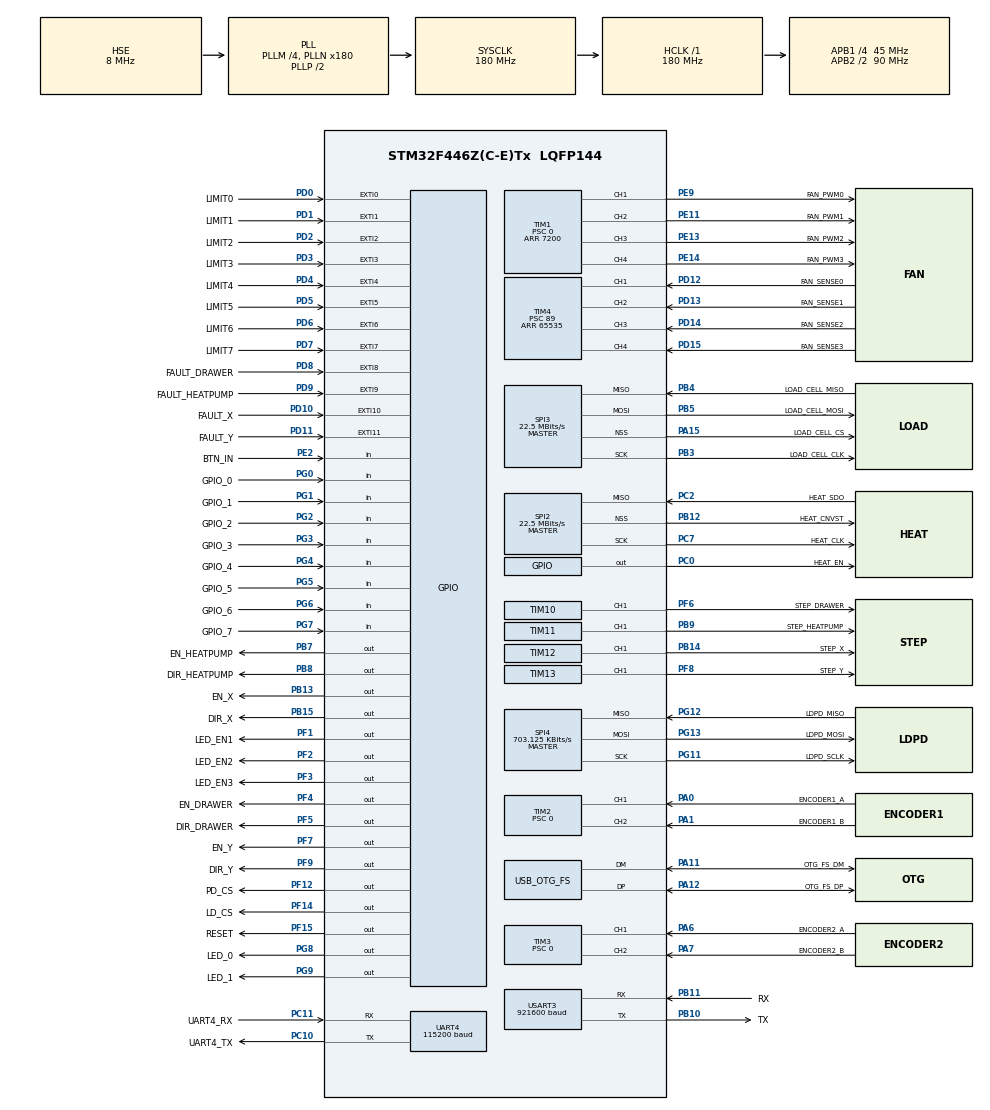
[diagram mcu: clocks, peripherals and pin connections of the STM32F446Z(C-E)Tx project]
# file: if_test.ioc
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Dma.Request0=USART3_RX
Dma.Request1=USART3_TX
Dma.USART3_RX.0.Direction=DMA_PERIPH_TO_MEMORY
Dma.USART3_RX.0.FIFOMode=DMA_FIFOMODE_DISABLE
Dma.USART3_RX.0.Instance=DMA1_Stream1
Dma.USART3_RX.0.MemDataAlignment=DMA_MDATAALIGN_BYTE
Dma.USART3_RX.0.MemInc=DMA_MINC_ENABLE
Dma.USART3_RX.0.Mode=DMA_NORMAL
Dma.USART3_RX.0.PeriphDataAlignment=DMA_PDATAALIGN_BYTE
Dma.USART3_RX.0.PeriphInc=DMA_PINC_DISABLE
Dma.USART3_RX.0.Priority=DMA_PRIORITY_LOW
Dma.USART3_TX.1.Direction=DMA_MEMORY_TO_PERIPH
Dma.USART3_TX.1.FIFOMode=DMA_FIFOMODE_DISABLE
Dma.USART3_TX.1.Instance=DMA1_Stream3
Dma.USART3_TX.1.MemDataAlignment=DMA_MDATAALIGN_BYTE
Dma.USART3_TX.1.MemInc=DMA_MINC_ENABLE
Dma.USART3_TX.1.Mode=DMA_NORMAL
Dma.USART3_TX.1.PeriphDataAlignment=DMA_PDATAALIGN_BYTE
Dma.USART3_TX.1.PeriphInc=DMA_PINC_DISABLE
Dma.USART3_TX.1.Priority=DMA_PRIORITY_LOW
FREERTOS.HEAP_NUMBER=4
FREERTOS.INCLUDE_eTaskGetState=1
FREERTOS.INCLUDE_pcTaskGetTaskName=0
FREERTOS.INCLUDE_uxTaskGetStackHighWaterMark=1
FREERTOS.INCLUDE_uxTaskGetStackHighWaterMark2=0
FREERTOS.INCLUDE_uxTaskPriorityGet=1
FREERTOS.INCLUDE_vTaskCleanUpResources=0
FREERTOS.INCLUDE_vTaskDelay=1
FREERTOS.INCLUDE_vTaskDelayUntil=1
FREERTOS.INCLUDE_vTaskDelete=1
FREERTOS.INCLUDE_vTaskPrioritySet=1
FREERTOS.INCLUDE_vTaskSuspend=1
FREERTOS.INCLUDE_xEventGroupSetBitFromISR=0
FREERTOS.INCLUDE_xQueueGetMutexHolder=1
FREERTOS.INCLUDE_xSemaphoreGetMutexHolder=0
FREERTOS.INCLUDE_xTaskAbortDelay=0
FREERTOS.INCLUDE_xTaskGetCurrentTaskHandle=1
FREERTOS.INCLUDE_xTaskGetHandle=0
FREERTOS.INCLUDE_xTaskGetSchedulerState=1
FREERTOS.INCLUDE_xTaskResumeFromISR=1
FREERTOS.INCLUDE_xTimerPendFunctionCall=1
FREERTOS.Tasks01=defaultTask,24,128,StartDefaultTask,Default,NULL,Dynamic,NULL,NULL
FREERTOS.configCHECK_FOR_STACK_OVERFLOW=0
FREERTOS.configENABLE_BACKWARD_COMPATIBILITY=1
FREERTOS.configENABLE_FPU=0
FREERTOS.configGENERATE_RUN_TIME_STATS=0
FREERTOS.configIDLE_SHOULD_YIELD=1
FREERTOS.configLIBRARY_LOWEST_INTERRUPT_PRIORITY=15
FREERTOS.configLIBRARY_MAX_SYSCALL_INTERRUPT_PRIORITY=5
FREERTOS.configMAX_CO_ROUTINE_PRIORITIES=2
FREERTOS.configMAX_TASK_NAME_LEN=16
FREERTOS.configMINIMAL_STACK_SIZE=128
FREERTOS.configQUEUE_REGISTRY_SIZE=8
FREERTOS.configRECORD_STACK_HIGH_ADDRESS=0
FREERTOS.configTICK_RATE_HZ=1000
FREERTOS.configTIMER_QUEUE_LENGTH=10
FREERTOS.configTIMER_TASK_PRIORITY=2
FREERTOS.configTIMER_TASK_STACK_DEPTH=256
FREERTOS.configTOTAL_HEAP_SIZE=40000
FREERTOS.configUSE_APPLICATION_TASK_TAG=0
FREERTOS.configUSE_COUNTING_SEMAPHORES=1
FREERTOS.configUSE_CO_ROUTINES=0
FREERTOS.configUSE_DAEMON_TASK_STARTUP_HOOK=0
FREERTOS.configUSE_IDLE_HOOK=0
FREERTOS.configUSE_MALLOC_FAILED_HOOK=0
FREERTOS.configUSE_MUTEXES=1
FREERTOS.configUSE_NEWLIB_REENTRANT=1
FREERTOS.configUSE_OS2_EVENTFLAGS_FROM_ISR=1
FREERTOS.configUSE_OS2_MUTEX=1
FREERTOS.configUSE_OS2_THREAD_ENUMERATE=1
FREERTOS.configUSE_OS2_THREAD_FLAGS=1
FREERTOS.configUSE_OS2_THREAD_SUSPEND_RESUME=1
FREERTOS.configUSE_OS2_TIMER=1
FREERTOS.configUSE_POSIX_ERRNO=0
FREERTOS.configUSE_PREEMPTION=1
FREERTOS.configUSE_RECURSIVE_MUTEXES=1
FREERTOS.configUSE_STATS_FORMATTING_FUNCTIONS=0
FREERTOS.configUSE_TASK_NOTIFICATIONS=1
FREERTOS.configUSE_TICKLESS_IDLE=0
FREERTOS.configUSE_TICK_HOOK=0
FREERTOS.configUSE_TRACE_FACILITY=1
FREERTOS.copyHeapFile=1
Mcu.Family=STM32F4
Mcu.Name=STM32F446Z(C-E)Tx
Mcu.Package=LQFP144
NVIC.DMA1_Stream1_IRQn=true\:5\:0\:false\:false\:true\:true\:false\:true\:true
NVIC.DMA1_Stream3_IRQn=true\:5\:0\:false\:false\:true\:true\:false\:true\:true
NVIC.EXTI0_IRQn=true\:5\:0\:false\:false\:true\:true\:true\:true\:true
NVIC.EXTI15_10_IRQn=true\:5\:0\:false\:false\:true\:true\:true\:true\:true
NVIC.EXTI1_IRQn=true\:5\:0\:false\:false\:true\:true\:true\:true\:true
NVIC.EXTI2_IRQn=true\:5\:0\:false\:false\:true\:true\:true\:true\:true
NVIC.EXTI3_IRQn=true\:5\:0\:false\:false\:true\:true\:true\:true\:true
NVIC.EXTI4_IRQn=true\:5\:0\:false\:false\:true\:true\:true\:true\:true
NVIC.EXTI9_5_IRQn=true\:5\:0\:false\:false\:true\:true\:true\:true\:true
NVIC.PriorityGroup=NVIC_PRIORITYGROUP_4
NVIC.SPI4_IRQn=true\:5\:0\:false\:false\:true\:true\:true\:true\:true
NVIC.TIM1_BRK_TIM9_IRQn=true\:5\:0\:false\:false\:true\:true\:true\:true\:true
NVIC.TIM1_TRG_COM_TIM11_IRQn=true\:5\:0\:false\:false\:true\:true\:true\:true\:true
NVIC.TIM1_UP_TIM10_IRQn=true\:5\:0\:false\:false\:true\:true\:true\:true\:true
NVIC.TIM4_IRQn=true\:5\:0\:false\:false\:true\:true\:true\:true\:true
NVIC.TIM8_BRK_TIM12_IRQn=true\:5\:0\:false\:false\:true\:true\:true\:true\:true
NVIC.TIM8_TRG_COM_TIM14_IRQn=true\:15\:0\:false\:false\:true\:false\:true\:true\:true
NVIC.TIM8_UP_TIM13_IRQn=true\:5\:0\:false\:false\:true\:true\:true\:true\:true
NVIC.TimeBase=TIM8_TRG_COM_TIM14_IRQn
NVIC.TimeBaseIP=TIM14
NVIC.USART3_IRQn=true\:5\:0\:false\:false\:true\:true\:true\:true\:true
PA0-WKUP.GPIO_Label=ENCODER1_A
PA0-WKUP.Signal=S_TIM2_CH1_ETR
PA1.GPIO_Label=ENCODER1_B
PA1.Signal=S_TIM2_CH2
PA11.GPIO_Label=OTG_FS_DM
PA11.Mode=Device_Only
PA11.Signal=USB_OTG_FS_DM
PA12.GPIO_Label=OTG_FS_DP
PA12.Mode=Device_Only
PA12.Signal=USB_OTG_FS_DP
PA13.Mode=Serial_Wire
PA13.Signal=SYS_JTMS-SWDIO
PA14.Mode=Serial_Wire
PA14.Signal=SYS_JTCK-SWCLK
PA15.GPIO_Label=LOAD_CELL_CS
PA15.Mode=NSS_Signal_Hard_Output
PA15.Signal=SPI3_NSS
PA6.GPIO_Label=ENCODER2_A
PA6.Signal=S_TIM3_CH1
PA7.GPIO_Label=ENCODER2_B
PA7.Signal=S_TIM3_CH2
PB10.GPIO_Label=TX
PB10.Mode=Asynchronous
PB10.Signal=USART3_TX
PB11.GPIO_Label=RX
PB11.Mode=Asynchronous
PB11.Signal=USART3_RX
PB12.GPIO_Label=HEAT_CNVST
PB12.Mode=NSS_Signal_Hard_Output
PB12.Signal=SPI2_NSS
PB13.GPIO_Label=EN_X
PB13.Signal=GPIO_Output
PB14.GPIO_Label=STEP_X
PB14.Signal=S_TIM12_CH1
PB15.GPIO_Label=DIR_X
PB15.Signal=GPIO_Output
PB3.GPIO_Label=LOAD_CELL_CLK
PB3.Mode=Full_Duplex_Master
PB3.Signal=SPI3_SCK
PB4.GPIO_Label=LOAD_CELL_MISO
PB4.Mode=Full_Duplex_Master
PB4.Signal=SPI3_MISO
PB5.GPIO_Label=LOAD_CELL_MOSI
PB5.Mode=Full_Duplex_Master
PB5.Signal=SPI3_MOSI
PB7.GPIO_Label=EN_HEATPUMP
PB7.Signal=GPIO_Output
PB8.GPIO_Label=DIR_HEATPUMP
PB8.Signal=GPIO_Output
PB9.GPIO_Label=STEP_HEATPUMP
PB9.Signal=S_TIM11_CH1
PC0.GPIO_Label=HEAT_EN
PC0.Signal=GPIO_Output
PC10.GPIO_Label=UART4_TX
PC10.Mode=Asynchronous
PC10.Signal=UART4_TX
PC11.GPIO_Label=UART4_RX
PC11.Mode=Asynchronous
PC11.Signal=UART4_RX
PC2.GPIO_Label=HEAT_SDO
PC2.Mode=RX_Only_Simplex_Unidirect_Master
PC2.Signal=SPI2_MISO
PC7.GPIO_Label=HEAT_CLK
PC7.Mode=RX_Only_Simplex_Unidirect_Master
PC7.Signal=SPI2_SCK
PD0.GPIO_Label=LIMIT0
PD0.GPIO_ModeDefaultEXTI=GPIO_MODE_IT_FALLING
PD0.Signal=GPXTI0
PD1.GPIO_Label=LIMIT1
PD1.GPIO_ModeDefaultEXTI=GPIO_MODE_IT_FALLING
PD1.Signal=GPXTI1
PD10.GPIO_Label=FAULT_X
PD10.GPIO_ModeDefaultEXTI=GPIO_MODE_IT_FALLING
PD10.Signal=GPXTI10
PD11.GPIO_Label=FAULT_Y
PD11.Signal=GPXTI11
PD12.GPIO_Label=FAN_SENSE0
PD12.Signal=S_TIM4_CH1
PD13.GPIO_Label=FAN_SENSE1
PD13.Signal=S_TIM4_CH2
PD14.GPIO_Label=FAN_SENSE2
PD14.Signal=S_TIM4_CH3
PD15.GPIO_Label=FAN_SENSE3
PD15.Signal=S_TIM4_CH4
PD2.GPIO_Label=LIMIT2
PD2.GPIO_ModeDefaultEXTI=GPIO_MODE_IT_FALLING
PD2.Signal=GPXTI2
PD3.GPIO_Label=LIMIT3
PD3.GPIO_ModeDefaultEXTI=GPIO_MODE_IT_FALLING
PD3.Signal=GPXTI3
PD4.GPIO_Label=LIMIT4
PD4.GPIO_ModeDefaultEXTI=GPIO_MODE_IT_FALLING
PD4.Signal=GPXTI4
PD5.GPIO_Label=LIMIT5
PD5.GPIO_ModeDefaultEXTI=GPIO_MODE_IT_FALLING
PD5.Signal=GPXTI5
PD6.GPIO_Label=LIMIT6
PD6.GPIO_ModeDefaultEXTI=GPIO_MODE_IT_FALLING
PD6.Signal=GPXTI6
PD7.GPIO_Label=LIMIT7
PD7.GPIO_ModeDefaultEXTI=GPIO_MODE_IT_FALLING
PD7.Signal=GPXTI7
PD8.GPIO_Label=FAULT_DRAWER
PD8.GPIO_ModeDefaultEXTI=GPIO_MODE_IT_FALLING
PD8.Signal=GPXTI8
PD9.GPIO_Label=FAULT_HEATPUMP
PD9.GPIO_ModeDefaultEXTI=GPIO_MODE_IT_FALLING
PD9.Signal=GPXTI9
PE11.GPIO_Label=FAN_PWM1
PE11.Signal=S_TIM1_CH2
PE13.GPIO_Label=FAN_PWM2
PE13.Signal=S_TIM1_CH3
PE14.GPIO_Label=FAN_PWM3
PE14.Signal=S_TIM1_CH4
PE2.GPIO_Label=BTN_IN
PE2.Signal=GPIO_Input
PE9.GPIO_Label=FAN_PWM0
PE9.Signal=S_TIM1_CH1
PF1.GPIO_Label=LED_EN1
PF1.Signal=GPIO_Output
PF12.GPIO_Label=PD_CS
PF12.Signal=GPIO_Output
PF14.GPIO_Label=LD_CS
PF14.Signal=GPIO_Output
PF15.GPIO_Label=RESET
PF15.Signal=GPIO_Output
PF2.GPIO_Label=LED_EN2
PF2.Signal=GPIO_Output
PF3.GPIO_Label=LED_EN3
PF3.Signal=GPIO_Output
PF4.GPIO_Label=EN_DRAWER
PF4.Signal=GPIO_Output
PF5.GPIO_Label=DIR_DRAWER
PF5.Signal=GPIO_Output
PF6.GPIO_Label=STEP_DRAWER
PF6.Signal=S_TIM10_CH1
PF7.GPIO_Label=EN_Y
PF7.Signal=GPIO_Output
PF8.GPIO_Label=STEP_Y
PF8.Signal=S_TIM13_CH1
PF9.GPIO_Label=DIR_Y
PF9.Signal=GPIO_Output
PG0.GPIO_Label=GPIO_0
PG0.Signal=GPIO_Input
PG1.GPIO_Label=GPIO_1
PG1.Signal=GPIO_Input
PG11.GPIO_Label=LDPD_SCLK
PG11.Mode=Full_Duplex_Master
PG11.Signal=SPI4_SCK
PG12.GPIO_Label=LDPD_MISO
PG12.Mode=Full_Duplex_Master
PG12.Signal=SPI4_MISO
PG13.GPIO_Label=LDPD_MOSI
PG13.Mode=Full_Duplex_Master
PG13.Signal=SPI4_MOSI
PG2.GPIO_Label=GPIO_2
PG2.Signal=GPIO_Input
PG3.GPIO_Label=GPIO_3
PG3.Signal=GPIO_Input
PG4.GPIO_Label=GPIO_4
PG4.Signal=GPIO_Input
PG5.GPIO_Label=GPIO_5
PG5.Signal=GPIO_Input
PG6.GPIO_Label=GPIO_6
PG6.Signal=GPIO_Input
PG7.GPIO_Label=GPIO_7
PG7.Signal=GPIO_Input
PG8.GPIO_Label=LED_0
PG8.Signal=GPIO_Output
PG9.GPIO_Label=LED_1
PG9.Signal=GPIO_Output
PH0-OSC_IN.Mode=HSE-External-Oscillator
PH0-OSC_IN.Signal=RCC_OSC_IN
PH1-OSC_OUT.Mode=HSE-External-Oscillator
PH1-OSC_OUT.Signal=RCC_OSC_OUT
ProjectManager.HeapSize=0x200
ProjectManager.StackSize=0x400
ProjectManager.TargetToolchain=CMake
RCC.AHBFreq_Value=180000000
RCC.APB1CLKDivider=RCC_HCLK_DIV4
RCC.APB1Freq_Value=45000000
RCC.APB1TimFreq_Value=90000000
RCC.APB2CLKDivider=RCC_HCLK_DIV2
RCC.APB2Freq_Value=90000000
RCC.APB2TimFreq_Value=180000000
RCC.CortexFreq_Value=180000000
RCC.HCLKFreq_Value=180000000
RCC.HSE_VALUE=8000000
RCC.PLLM=4
RCC.PLLN=180
RCC.PLLSAIM=8
RCC.PLLSAIP=RCC_PLLSAIP_DIV4
RCC.PWREXT_OverDrive=PWREXT_OverDrive_ACTIVATED
RCC.SYSCLKFreq_VALUE=180000000
RCC.SYSCLKSource=RCC_SYSCLKSOURCE_PLLCLK
RCC.USBCLockSelection=RCC_CLK48CLKSOURCE_PLLSAIP
RCC.USBFreq_Value=48000000
RCC.VCOOutputFreq_Value=360000000
SH.S_TIM10_CH1.0=TIM10_CH1,PWM Generation1 CH1
SH.S_TIM11_CH1.0=TIM11_CH1,PWM Generation1 CH1
SH.S_TIM12_CH1.0=TIM12_CH1,PWM Generation1 CH1
SH.S_TIM13_CH1.0=TIM13_CH1,PWM Generation1 CH1
SH.S_TIM1_CH1.0=TIM1_CH1,PWM Generation1 CH1
SH.S_TIM1_CH2.0=TIM1_CH2,PWM Generation2 CH2
SH.S_TIM1_CH3.0=TIM1_CH3,PWM Generation3 CH3
SH.S_TIM1_CH4.0=TIM1_CH4,PWM Generation4 CH4
SH.S_TIM2_CH1_ETR.0=TIM2_CH1,Encoder_Interface
SH.S_TIM2_CH2.0=TIM2_CH2,Encoder_Interface
SH.S_TIM3_CH1.0=TIM3_CH1,Encoder_Interface
SH.S_TIM3_CH2.0=TIM3_CH2,Encoder_Interface
SH.S_TIM4_CH1.0=TIM4_CH1,Input_Capture1_from_TI1
SH.S_TIM4_CH2.0=TIM4_CH2,Input_Capture2_from_TI2
SH.S_TIM4_CH3.0=TIM4_CH3,Input_Capture3_from_TI3
SH.S_TIM4_CH4.0=TIM4_CH4,Input_Capture4_from_TI4
SPI2.BaudRatePrescaler=SPI_BAUDRATEPRESCALER_2
SPI2.CLKPhase=SPI_PHASE_1EDGE
SPI2.CLKPolarity=SPI_POLARITY_LOW
SPI2.CRCCalculation=SPI_CRCCALCULATION_DISABLE
SPI2.CalculateBaudRate=22.5 MBits/s
SPI2.DataSize=SPI_DATASIZE_8BIT
SPI2.Direction=SPI_DIRECTION_2LINES_RXONLY
SPI2.FirstBit=SPI_FIRSTBIT_MSB
SPI2.Mode=SPI_MODE_MASTER
SPI2.NSS=SPI_NSS_HARD_OUTPUT
SPI2.TIMode=SPI_TIMODE_DISABLE
SPI2.VirtualNSS=VM_NSSHARD
SPI2.VirtualType=VM_MASTER
SPI3.BaudRatePrescaler=SPI_BAUDRATEPRESCALER_2
SPI3.CLKPhase=SPI_PHASE_1EDGE
SPI3.CLKPolarity=SPI_POLARITY_LOW
SPI3.CRCCalculation=SPI_CRCCALCULATION_DISABLE
SPI3.CalculateBaudRate=22.5 MBits/s
SPI3.DataSize=SPI_DATASIZE_8BIT
SPI3.Direction=SPI_DIRECTION_2LINES
SPI3.FirstBit=SPI_FIRSTBIT_MSB
SPI3.Mode=SPI_MODE_MASTER
SPI3.NSS=SPI_NSS_HARD_OUTPUT
SPI3.TIMode=SPI_TIMODE_DISABLE
SPI3.VirtualNSS=VM_NSSHARD
SPI3.VirtualType=VM_MASTER
SPI4.BaudRatePrescaler=SPI_BAUDRATEPRESCALER_128
SPI4.CLKPhase=SPI_PHASE_2EDGE
SPI4.CLKPolarity=SPI_POLARITY_HIGH
SPI4.CRCCalculation=SPI_CRCCALCULATION_DISABLE
SPI4.CalculateBaudRate=703.125 KBits/s
SPI4.DataSize=SPI_DATASIZE_8BIT
SPI4.Direction=SPI_DIRECTION_2LINES
SPI4.FirstBit=SPI_FIRSTBIT_MSB
SPI4.Mode=SPI_MODE_MASTER
SPI4.NSS=SPI_NSS_SOFT
SPI4.TIMode=SPI_TIMODE_DISABLE
SPI4.VirtualType=VM_MASTER
TIM1.AutoReloadPreload=TIM_AUTORELOAD_PRELOAD_DISABLE
TIM1.AutomaticOutput=TIM_AUTOMATICOUTPUT_DISABLE
TIM1.BreakPolarity=TIM_BREAKPOLARITY_HIGH
TIM1.BreakState=TIM_BREAK_DISABLE
TIM1.Channel-PWM\ Generation1\ CH1=TIM_CHANNEL_1
TIM1.Channel-PWM\ Generation2\ CH2=TIM_CHANNEL_2
TIM1.Channel-PWM\ Generation3\ CH3=TIM_CHANNEL_3
TIM1.Channel-PWM\ Generation4\ CH4=TIM_CHANNEL_4
TIM1.ClockDivision=TIM_CLOCKDIVISION_DIV1
TIM1.CounterMode=TIM_COUNTERMODE_UP
TIM1.LockLevel=TIM_LOCKLEVEL_OFF
TIM1.OC1Preload_PWM=ENABLE
TIM1.OC2Preload_PWM=ENABLE
TIM1.OC3Preload_PWM=ENABLE
TIM1.OC4Preload_PWM=ENABLE
TIM1.OCFastMode_PWM-PWM\ Generation1\ CH1=TIM_OCFAST_DISABLE
TIM1.OCFastMode_PWM-PWM\ Generation2\ CH2=TIM_OCFAST_DISABLE
TIM1.OCFastMode_PWM-PWM\ Generation3\ CH3=TIM_OCFAST_DISABLE
TIM1.OCFastMode_PWM-PWM\ Generation4\ CH4=TIM_OCFAST_DISABLE
TIM1.OCIdleState_1=TIM_OCIDLESTATE_RESET
TIM1.OCIdleState_2=TIM_OCIDLESTATE_RESET
TIM1.OCIdleState_3=TIM_OCIDLESTATE_RESET
TIM1.OCIdleState_4=TIM_OCIDLESTATE_RESET
TIM1.OCMode_PWM-PWM\ Generation1\ CH1=TIM_OCMODE_PWM1
TIM1.OCMode_PWM-PWM\ Generation2\ CH2=TIM_OCMODE_PWM1
TIM1.OCMode_PWM-PWM\ Generation3\ CH3=TIM_OCMODE_PWM1
TIM1.OCMode_PWM-PWM\ Generation4\ CH4=TIM_OCMODE_PWM1
TIM1.OCPolarity_1=TIM_OCPOLARITY_HIGH
TIM1.OCPolarity_2=TIM_OCPOLARITY_HIGH
TIM1.OCPolarity_3=TIM_OCPOLARITY_HIGH
TIM1.OCPolarity_4=TIM_OCPOLARITY_HIGH
TIM1.OffStateIDLEMode=TIM_OSSI_DISABLE
TIM1.OffStateRunMode=TIM_OSSR_DISABLE
TIM1.Period=7200
TIM1.Prescaler=0
TIM1.Pulse-PWM\ Generation1\ CH1=0
TIM1.Pulse-PWM\ Generation2\ CH2=0
TIM1.Pulse-PWM\ Generation3\ CH3=0
TIM1.Pulse-PWM\ Generation4\ CH4=0
TIM1.RepetitionCounter=0
TIM1.TIM_MasterOutputTrigger=TIM_TRGO_RESET
TIM1.TIM_MasterSlaveMode=TIM_MASTERSLAVEMODE_DISABLE
TIM10.AutoReloadPreload=TIM_AUTORELOAD_PRELOAD_ENABLE
TIM10.Channel=TIM_CHANNEL_1
TIM10.ClockDivision=TIM_CLOCKDIVISION_DIV1
TIM10.CounterMode=TIM_COUNTERMODE_UP
TIM10.OC1Preload_PWM=ENABLE
TIM10.OCFastMode_PWM=TIM_OCFAST_DISABLE
TIM10.OCMode_PWM=TIM_OCMODE_PWM1
TIM10.OCPolarity_1=TIM_OCPOLARITY_HIGH
TIM10.Period=65535
TIM10.Prescaler=1499
TIM10.Pulse=0
TIM11.AutoReloadPreload=TIM_AUTORELOAD_PRELOAD_ENABLE
TIM11.Channel=TIM_CHANNEL_1
TIM11.ClockDivision=TIM_CLOCKDIVISION_DIV1
TIM11.CounterMode=TIM_COUNTERMODE_UP
TIM11.OC1Preload_PWM=ENABLE
TIM11.OCFastMode_PWM=TIM_OCFAST_DISABLE
TIM11.OCMode_PWM=TIM_OCMODE_PWM1
TIM11.OCPolarity_1=TIM_OCPOLARITY_HIGH
TIM11.Period=65535
TIM11.Prescaler=1499
TIM11.Pulse=0
TIM12.AutoReloadPreload=TIM_AUTORELOAD_PRELOAD_ENABLE
TIM12.Channel-PWM\ Generation1\ CH1=TIM_CHANNEL_1
TIM12.ClockDivision=TIM_CLOCKDIVISION_DIV1
TIM12.CounterMode=TIM_COUNTERMODE_UP
TIM12.OC1Preload_PWM=ENABLE
TIM12.OCFastMode_PWM-PWM\ Generation1\ CH1=TIM_OCFAST_DISABLE
TIM12.OCMode_PWM-PWM\ Generation1\ CH1=TIM_OCMODE_PWM1
TIM12.OCPolarity_1=TIM_OCPOLARITY_HIGH
TIM12.Period=65535
TIM12.Prescaler=749
TIM12.Pulse-PWM\ Generation1\ CH1=0
TIM13.AutoReloadPreload=TIM_AUTORELOAD_PRELOAD_ENABLE
TIM13.Channel=TIM_CHANNEL_1
TIM13.ClockDivision=TIM_CLOCKDIVISION_DIV1
TIM13.CounterMode=TIM_COUNTERMODE_UP
TIM13.OC1Preload_PWM=ENABLE
TIM13.OCFastMode_PWM=TIM_OCFAST_DISABLE
TIM13.OCMode_PWM=TIM_OCMODE_PWM1
TIM13.OCPolarity_1=TIM_OCPOLARITY_HIGH
TIM13.Period=65535
TIM13.Prescaler=749
TIM13.Pulse=0
TIM2.AutoReloadPreload=TIM_AUTORELOAD_PRELOAD_DISABLE
TIM2.ClockDivision=TIM_CLOCKDIVISION_DIV1
TIM2.CounterMode=TIM_COUNTERMODE_UP
TIM2.EncoderMode=TIM_ENCODERMODE_TI12
TIM2.IC1Filter=0
TIM2.IC1Polarity=TIM_ICPOLARITY_RISING
TIM2.IC1Prescaler=TIM_ICPSC_DIV1
TIM2.IC1Selection=TIM_ICSELECTION_DIRECTTI
TIM2.IC2Filter=0
TIM2.IC2Polarity=TIM_ICPOLARITY_RISING
TIM2.IC2Prescaler=TIM_ICPSC_DIV1
TIM2.IC2Selection=TIM_ICSELECTION_DIRECTTI
TIM2.Period=65535
TIM2.Prescaler=0
TIM2.TIM_MasterOutputTrigger=TIM_TRGO_RESET
TIM2.TIM_MasterSlaveMode=TIM_MASTERSLAVEMODE_DISABLE
TIM3.AutoReloadPreload=TIM_AUTORELOAD_PRELOAD_DISABLE
TIM3.ClockDivision=TIM_CLOCKDIVISION_DIV1
TIM3.CounterMode=TIM_COUNTERMODE_UP
TIM3.EncoderMode=TIM_ENCODERMODE_TI12
TIM3.IC1Filter=0
TIM3.IC1Polarity=TIM_ICPOLARITY_RISING
TIM3.IC1Prescaler=TIM_ICPSC_DIV1
TIM3.IC1Selection=TIM_ICSELECTION_DIRECTTI
TIM3.IC2Filter=0
TIM3.IC2Polarity=TIM_ICPOLARITY_RISING
TIM3.IC2Prescaler=TIM_ICPSC_DIV1
TIM3.IC2Selection=TIM_ICSELECTION_DIRECTTI
TIM3.Period=65535
TIM3.Prescaler=0
TIM3.TIM_MasterOutputTrigger=TIM_TRGO_RESET
TIM3.TIM_MasterSlaveMode=TIM_MASTERSLAVEMODE_DISABLE
TIM4.AutoReloadPreload=TIM_AUTORELOAD_PRELOAD_DISABLE
TIM4.Channel-Input_Capture1_from_TI1=TIM_CHANNEL_1
TIM4.Channel-Input_Capture2_from_TI2=TIM_CHANNEL_2
TIM4.Channel-Input_Capture3_from_TI3=TIM_CHANNEL_3
TIM4.Channel-Input_Capture4_from_TI4=TIM_CHANNEL_4
TIM4.ClockDivision=TIM_CLOCKDIVISION_DIV1
TIM4.CounterMode=TIM_COUNTERMODE_UP
TIM4.ICFilter_CH1=4
TIM4.ICFilter_CH2=4
TIM4.ICFilter_CH3=4
TIM4.ICFilter_CH4=4
TIM4.ICPolarity_CH1=TIM_INPUTCHANNELPOLARITY_RISING
TIM4.ICPolarity_CH2=TIM_INPUTCHANNELPOLARITY_RISING
TIM4.ICPolarity_CH3=TIM_INPUTCHANNELPOLARITY_RISING
TIM4.ICPolarity_CH4=TIM_INPUTCHANNELPOLARITY_RISING
TIM4.ICPrescaler-Input_Capture1_from_TI1=TIM_ICPSC_DIV1
TIM4.ICPrescaler-Input_Capture2_from_TI2=TIM_ICPSC_DIV1
TIM4.ICPrescaler-Input_Capture3_from_TI3=TIM_ICPSC_DIV1
TIM4.ICPrescaler-Input_Capture4_from_TI4=TIM_ICPSC_DIV1
TIM4.ICSelection-Input_Capture1_from_TI1=TIM_ICSELECTION_DIRECTTI
TIM4.ICSelection-Input_Capture2_from_TI2=TIM_ICSELECTION_DIRECTTI
TIM4.ICSelection-Input_Capture3_from_TI3=TIM_ICSELECTION_DIRECTTI
TIM4.ICSelection-Input_Capture4_from_TI4=TIM_ICSELECTION_DIRECTTI
TIM4.Period=65535
TIM4.Prescaler=89
TIM4.TIM_MasterOutputTrigger=TIM_TRGO_RESET
TIM4.TIM_MasterSlaveMode=TIM_MASTERSLAVEMODE_DISABLE
TIM7.Prescaler=168-1
TIM9.AutoReloadPreload=TIM_AUTORELOAD_PRELOAD_ENABLE
TIM9.Channel-Output\ Compare1\ No\ Output=TIM_CHANNEL_1
TIM9.Period=5000
TIM9.Prescaler=179
UART4.BaudRate=115200
UART4.Mode=MODE_TX_RX
UART4.OverSampling=UART_OVERSAMPLING_16
UART4.Parity=PARITY_NONE
UART4.StopBits=UART_STOPBITS_1
UART4.VirtualMode=Asynchronous
UART4.WordLength=WORDLENGTH_8B
USART3.BaudRate=921600
USART3.Mode=MODE_TX_RX
USART3.OverSampling=UART_OVERSAMPLING_16
USART3.Parity=PARITY_NONE
USART3.StopBits=STOPBITS_1
USART3.VirtualMode=VM_ASYNC
USART3.WordLength=WORDLENGTH_8B
USB_OTG_FS.Sof_enable=DISABLE
USB_OTG_FS.VirtualMode=Device_Only
USB_OTG_FS.low_power_enable=DISABLE
USB_OTG_FS.lpm_enable=DISABLE
USB_OTG_FS.vbus_sensing_enable=DISABLE
VP_CRC_VS_CRC.Mode=CRC_Activate
VP_FREERTOS_VS_CMSIS_V2.Mode=CMSIS_V2
VP_SYS_VS_tim14.Mode=TIM14
VP_TIM10_VS_ClockSourceINT.Mode=Enable_Timer
VP_TIM11_VS_ClockSourceINT.Mode=Enable_Timer
VP_TIM12_VS_ClockSourceINT.Mode=Internal
VP_TIM13_VS_ClockSourceINT.Mode=Enable_Timer
VP_TIM1_VS_ClockSourceINT.Mode=Internal
VP_TIM4_VS_ClockSourceINT.Mode=Internal
VP_TIM7_VS_ClockSourceINT.Mode=Enable_Timer
VP_TIM9_VS_ClockSourceINT.Mode=Internal
VP_TIM9_VS_no_output1.Mode=Output Compare1 No Output
board=custom

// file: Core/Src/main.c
/* USER CODE BEGIN Header */
/**
  ******************************************************************************
  * @file           : main.c
  * @brief          : Main program body
  ******************************************************************************
  * @attention
  *
  * Copyright (c) 2026 STMicroelectronics.
  * All rights reserved.
  *
  * This software is licensed under terms that can be found in the LICENSE file
  * in the root directory of this software component.
  * If no LICENSE file comes with this software, it is provided AS-IS.
  *
  ******************************************************************************
  */
/* USER CODE END Header */
#include "main.h"
#include "cmsis_os.h"

/* USER CODE BEGIN Includes */
#include "optics.h"
#include "logging.h"
#include "util.h"

/* USER CODE END Includes */

CRC_HandleTypeDef hcrc;

SPI_HandleTypeDef hspi2;
SPI_HandleTypeDef hspi3;
SPI_HandleTypeDef hspi4;

TIM_HandleTypeDef htim1;
TIM_HandleTypeDef htim2;
TIM_HandleTypeDef htim3;
TIM_HandleTypeDef htim4;
TIM_HandleTypeDef htim7;
TIM_HandleTypeDef htim9;
TIM_HandleTypeDef htim10;
TIM_HandleTypeDef htim11;
TIM_HandleTypeDef htim12;
TIM_HandleTypeDef htim13;

UART_HandleTypeDef huart4;
UART_HandleTypeDef huart3;
DMA_HandleTypeDef hdma_usart3_rx;
DMA_HandleTypeDef hdma_usart3_tx;

PCD_HandleTypeDef hpcd_USB_OTG_FS;

/* Definitions for defaultTask */
osThreadId_t defaultTaskHandle;
const osThreadAttr_t defaultTask_attributes = {
  .name = "defaultTask",
  .stack_size = 128 * 4,
  .priority = (osPriority_t) osPriorityNormal,
};
/* USER CODE BEGIN PV */

/* Definitions for opticsTask */
osThreadId_t opticsTaskHandle;
const osThreadAttr_t opticsTask_attributes = {
  .name = "opticsTask",
  .stack_size = 512 * 4,
  .priority = (osPriority_t) osPriorityNormal,
};
/* USER CODE END PV */

void SystemClock_Config(void);
static void MX_GPIO_Init(void);
static void MX_DMA_Init(void);
static void MX_TIM10_Init(void);
static void MX_TIM2_Init(void);
static void MX_USART3_UART_Init(void);
static void MX_TIM3_Init(void);
static void MX_TIM11_Init(void);
static void MX_TIM12_Init(void);
static void MX_TIM13_Init(void);
static void MX_SPI2_Init(void);
static void MX_TIM1_Init(void);
static void MX_TIM4_Init(void);
static void MX_SPI3_Init(void);
static void MX_SPI4_Init(void);
static void MX_UART4_Init(void);
static void MX_USB_OTG_FS_PCD_Init(void);
static void MX_TIM9_Init(void);
static void MX_CRC_Init(void);
static void MX_TIM7_Init(void);
void StartDefaultTask(void *argument);

/* USER CODE BEGIN PFP */
void StartOpticsTask(void *argument);

/* USER CODE END PFP */

int main(void)
{

  /* MCU Configuration--------------------------------------------------------*/

  /* Reset of all peripherals, Initializes the Flash interface and the Systick. */
  HAL_Init();

  /* Configure the system clock */
  SystemClock_Config();

  /* Initialize all configured peripherals */
  MX_GPIO_Init();
  MX_DMA_Init();
  MX_TIM10_Init();
  MX_TIM2_Init();
  MX_USART3_UART_Init();
  MX_TIM3_Init();
  MX_TIM11_Init();
  MX_TIM12_Init();
  MX_TIM13_Init();
  MX_SPI2_Init();
  MX_TIM1_Init();
  MX_TIM4_Init();
  MX_SPI3_Init();
  MX_SPI4_Init();
  MX_UART4_Init();
  MX_USB_OTG_FS_PCD_Init();
  MX_TIM9_Init();
  MX_CRC_Init();
  MX_TIM7_Init();
  /* USER CODE BEGIN 2 */
  Delay_Init();
  init_dma_logging();

  printf("\033c");
  printf("Interface Demo\r\n");
  printf("CPU Clock Frequency: %lu MHz\r\n\r\n", HAL_RCC_GetSysClockFreq() / 1000000);

  /* USER CODE END 2 */

  /* Init scheduler */
  osKernelInitialize();

  /* Create the thread(s) */
  /* creation of defaultTask */
  defaultTaskHandle = osThreadNew(StartDefaultTask, NULL, &defaultTask_attributes);

  /* USER CODE BEGIN RTOS_THREADS */
  /* add threads, ... */
  opticsTaskHandle = osThreadNew(StartOpticsTask, NULL, &opticsTask_attributes);
  /* USER CODE END RTOS_THREADS */

  /* Start scheduler */
  osKernelStart();

  /* We should never get here as control is now taken by the scheduler */

  /* Infinite loop */
  while (1)
  {

  }
}

void SystemClock_Config(void)
{
  RCC_OscInitTypeDef RCC_OscInitStruct = {0};
  RCC_ClkInitTypeDef RCC_ClkInitStruct = {0};

  /** Configure the main internal regulator output voltage
  */
  __HAL_RCC_PWR_CLK_ENABLE();
  __HAL_PWR_VOLTAGESCALING_CONFIG(PWR_REGULATOR_VOLTAGE_SCALE1);

  /** Initializes the RCC Oscillators according to the specified parameters
  * in the RCC_OscInitTypeDef structure.
  */
  RCC_OscInitStruct.OscillatorType = RCC_OSCILLATORTYPE_HSE;
  RCC_OscInitStruct.HSEState = RCC_HSE_ON;
  RCC_OscInitStruct.PLL.PLLState = RCC_PLL_ON;
  RCC_OscInitStruct.PLL.PLLSource = RCC_PLLSOURCE_HSE;
  RCC_OscInitStruct.PLL.PLLM = 4;
  RCC_OscInitStruct.PLL.PLLN = 180;
  RCC_OscInitStruct.PLL.PLLP = RCC_PLLP_DIV2;
  RCC_OscInitStruct.PLL.PLLQ = 2;
  RCC_OscInitStruct.PLL.PLLR = 2;
  if (HAL_RCC_OscConfig(&RCC_OscInitStruct) != HAL_OK)
  {
    Error_Handler();
  }

  /** Activate the Over-Drive mode
  */
  if (HAL_PWREx_EnableOverDrive() != HAL_OK)
  {
    Error_Handler();
  }

  /** Initializes the CPU, AHB and APB buses clocks
  */
  RCC_ClkInitStruct.ClockType = RCC_CLOCKTYPE_HCLK|RCC_CLOCKTYPE_SYSCLK
                              |RCC_CLOCKTYPE_PCLK1|RCC_CLOCKTYPE_PCLK2;
  RCC_ClkInitStruct.SYSCLKSource = RCC_SYSCLKSOURCE_PLLCLK;
  RCC_ClkInitStruct.AHBCLKDivider = RCC_SYSCLK_DIV1;
  RCC_ClkInitStruct.APB1CLKDivider = RCC_HCLK_DIV4;
  RCC_ClkInitStruct.APB2CLKDivider = RCC_HCLK_DIV2;

  if (HAL_RCC_ClockConfig(&RCC_ClkInitStruct, FLASH_LATENCY_5) != HAL_OK)
  {
    Error_Handler();
  }
}

static void MX_CRC_Init(void)
{

  hcrc.Instance = CRC;
  if (HAL_CRC_Init(&hcrc) != HAL_OK)
  {
    Error_Handler();
  }

}

static void MX_SPI2_Init(void)
{

  /* SPI2 parameter configuration*/
  hspi2.Instance = SPI2;
  hspi2.Init.Mode = SPI_MODE_MASTER;
  hspi2.Init.Direction = SPI_DIRECTION_2LINES_RXONLY;
  hspi2.Init.DataSize = SPI_DATASIZE_8BIT;
  hspi2.Init.CLKPolarity = SPI_POLARITY_LOW;
  hspi2.Init.CLKPhase = SPI_PHASE_1EDGE;
  hspi2.Init.NSS = SPI_NSS_HARD_OUTPUT;
  hspi2.Init.BaudRatePrescaler = SPI_BAUDRATEPRESCALER_2;
  hspi2.Init.FirstBit = SPI_FIRSTBIT_MSB;
  hspi2.Init.TIMode = SPI_TIMODE_DISABLE;
  hspi2.Init.CRCCalculation = SPI_CRCCALCULATION_DISABLE;
  hspi2.Init.CRCPolynomial = 10;
  if (HAL_SPI_Init(&hspi2) != HAL_OK)
  {
    Error_Handler();
  }

}

static void MX_SPI3_Init(void)
{

  /* SPI3 parameter configuration*/
  hspi3.Instance = SPI3;
  hspi3.Init.Mode = SPI_MODE_MASTER;
  hspi3.Init.Direction = SPI_DIRECTION_2LINES;
  hspi3.Init.DataSize = SPI_DATASIZE_8BIT;
  hspi3.Init.CLKPolarity = SPI_POLARITY_LOW;
  hspi3.Init.CLKPhase = SPI_PHASE_1EDGE;
  hspi3.Init.NSS = SPI_NSS_HARD_OUTPUT;
  hspi3.Init.BaudRatePrescaler = SPI_BAUDRATEPRESCALER_2;
  hspi3.Init.FirstBit = SPI_FIRSTBIT_MSB;
  hspi3.Init.TIMode = SPI_TIMODE_DISABLE;
  hspi3.Init.CRCCalculation = SPI_CRCCALCULATION_DISABLE;
  hspi3.Init.CRCPolynomial = 10;
  if (HAL_SPI_Init(&hspi3) != HAL_OK)
  {
    Error_Handler();
  }

}

static void MX_SPI4_Init(void)
{

  /* SPI4 parameter configuration*/
  hspi4.Instance = SPI4;
  hspi4.Init.Mode = SPI_MODE_MASTER;
  hspi4.Init.Direction = SPI_DIRECTION_2LINES;
  hspi4.Init.DataSize = SPI_DATASIZE_8BIT;
  hspi4.Init.CLKPolarity = SPI_POLARITY_HIGH;
  hspi4.Init.CLKPhase = SPI_PHASE_2EDGE;
  hspi4.Init.NSS = SPI_NSS_SOFT;
  hspi4.Init.BaudRatePrescaler = SPI_BAUDRATEPRESCALER_256;
  hspi4.Init.FirstBit = SPI_FIRSTBIT_MSB;
  hspi4.Init.TIMode = SPI_TIMODE_DISABLE;
  hspi4.Init.CRCCalculation = SPI_CRCCALCULATION_DISABLE;
  hspi4.Init.CRCPolynomial = 10;
  if (HAL_SPI_Init(&hspi4) != HAL_OK)
  {
    Error_Handler();
  }

}

static void MX_TIM1_Init(void)
{

  TIM_ClockConfigTypeDef sClockSourceConfig = {0};
  TIM_MasterConfigTypeDef sMasterConfig = {0};
  TIM_OC_InitTypeDef sConfigOC = {0};
  TIM_BreakDeadTimeConfigTypeDef sBreakDeadTimeConfig = {0};

  htim1.Instance = TIM1;
  htim1.Init.Prescaler = 0;
  htim1.Init.CounterMode = TIM_COUNTERMODE_UP;
  htim1.Init.Period = 7200;
  htim1.Init.ClockDivision = TIM_CLOCKDIVISION_DIV1;
  htim1.Init.RepetitionCounter = 0;
  htim1.Init.AutoReloadPreload = TIM_AUTORELOAD_PRELOAD_DISABLE;
  if (HAL_TIM_Base_Init(&htim1) != HAL_OK)
  {
    Error_Handler();
  }
  sClockSourceConfig.ClockSource = TIM_CLOCKSOURCE_INTERNAL;
  if (HAL_TIM_ConfigClockSource(&htim1, &sClockSourceConfig) != HAL_OK)
  {
    Error_Handler();
  }
  if (HAL_TIM_PWM_Init(&htim1) != HAL_OK)
  {
    Error_Handler();
  }
  sMasterConfig.MasterOutputTrigger = TIM_TRGO_RESET;
  sMasterConfig.MasterSlaveMode = TIM_MASTERSLAVEMODE_DISABLE;
  if (HAL_TIMEx_MasterConfigSynchronization(&htim1, &sMasterConfig) != HAL_OK)
  {
    Error_Handler();
  }
  sConfigOC.OCMode = TIM_OCMODE_PWM1;
  sConfigOC.Pulse = 0;
  sConfigOC.OCPolarity = TIM_OCPOLARITY_HIGH;
  sConfigOC.OCNPolarity = TIM_OCNPOLARITY_HIGH;
  sConfigOC.OCFastMode = TIM_OCFAST_DISABLE;
  sConfigOC.OCIdleState = TIM_OCIDLESTATE_RESET;
  sConfigOC.OCNIdleState = TIM_OCNIDLESTATE_RESET;
  if (HAL_TIM_PWM_ConfigChannel(&htim1, &sConfigOC, TIM_CHANNEL_1) != HAL_OK)
  {
    Error_Handler();
  }
  if (HAL_TIM_PWM_ConfigChannel(&htim1, &sConfigOC, TIM_CHANNEL_2) != HAL_OK)
  {
    Error_Handler();
  }
  if (HAL_TIM_PWM_ConfigChannel(&htim1, &sConfigOC, TIM_CHANNEL_3) != HAL_OK)
  {
    Error_Handler();
  }
  if (HAL_TIM_PWM_ConfigChannel(&htim1, &sConfigOC, TIM_CHANNEL_4) != HAL_OK)
  {
    Error_Handler();
  }
  sBreakDeadTimeConfig.OffStateRunMode = TIM_OSSR_DISABLE;
  sBreakDeadTimeConfig.OffStateIDLEMode = TIM_OSSI_DISABLE;
  sBreakDeadTimeConfig.LockLevel = TIM_LOCKLEVEL_OFF;
  sBreakDeadTimeConfig.DeadTime = 0;
  sBreakDeadTimeConfig.BreakState = TIM_BREAK_DISABLE;
  sBreakDeadTimeConfig.BreakPolarity = TIM_BREAKPOLARITY_HIGH;
  sBreakDeadTimeConfig.AutomaticOutput = TIM_AUTOMATICOUTPUT_DISABLE;
  if (HAL_TIMEx_ConfigBreakDeadTime(&htim1, &sBreakDeadTimeConfig) != HAL_OK)
  {
    Error_Handler();
  }
  HAL_TIM_MspPostInit(&htim1);

}

static void MX_TIM2_Init(void)
{

  TIM_Encoder_InitTypeDef sConfig = {0};
  TIM_MasterConfigTypeDef sMasterConfig = {0};

  htim2.Instance = TIM2;
  htim2.Init.Prescaler = 0;
  htim2.Init.CounterMode = TIM_COUNTERMODE_UP;
  htim2.Init.Period = 65535;
  htim2.Init.ClockDivision = TIM_CLOCKDIVISION_DIV1;
  htim2.Init.AutoReloadPreload = TIM_AUTORELOAD_PRELOAD_DISABLE;
  sConfig.EncoderMode = TIM_ENCODERMODE_TI12;
  sConfig.IC1Polarity = TIM_ICPOLARITY_RISING;
  sConfig.IC1Selection = TIM_ICSELECTION_DIRECTTI;
  sConfig.IC1Prescaler = TIM_ICPSC_DIV1;
  sConfig.IC1Filter = 0;
  sConfig.IC2Polarity = TIM_ICPOLARITY_RISING;
  sConfig.IC2Selection = TIM_ICSELECTION_DIRECTTI;
  sConfig.IC2Prescaler = TIM_ICPSC_DIV1;
  sConfig.IC2Filter = 0;
  if (HAL_TIM_Encoder_Init(&htim2, &sConfig) != HAL_OK)
  {
    Error_Handler();
  }
  sMasterConfig.MasterOutputTrigger = TIM_TRGO_RESET;
  sMasterConfig.MasterSlaveMode = TIM_MASTERSLAVEMODE_DISABLE;
  if (HAL_TIMEx_MasterConfigSynchronization(&htim2, &sMasterConfig) != HAL_OK)
  {
    Error_Handler();
  }

}

static void MX_TIM3_Init(void)
{

  TIM_Encoder_InitTypeDef sConfig = {0};
  TIM_MasterConfigTypeDef sMasterConfig = {0};

  htim3.Instance = TIM3;
  htim3.Init.Prescaler = 0;
  htim3.Init.CounterMode = TIM_COUNTERMODE_UP;
  htim3.Init.Period = 65535;
  htim3.Init.ClockDivision = TIM_CLOCKDIVISION_DIV1;
  htim3.Init.AutoReloadPreload = TIM_AUTORELOAD_PRELOAD_DISABLE;
  sConfig.EncoderMode = TIM_ENCODERMODE_TI12;
  sConfig.IC1Polarity = TIM_ICPOLARITY_RISING;
  sConfig.IC1Selection = TIM_ICSELECTION_DIRECTTI;
  sConfig.IC1Prescaler = TIM_ICPSC_DIV1;
  sConfig.IC1Filter = 0;
  sConfig.IC2Polarity = TIM_ICPOLARITY_RISING;
  sConfig.IC2Selection = TIM_ICSELECTION_DIRECTTI;
  sConfig.IC2Prescaler = TIM_ICPSC_DIV1;
  sConfig.IC2Filter = 0;
  if (HAL_TIM_Encoder_Init(&htim3, &sConfig) != HAL_OK)
  {
    Error_Handler();
  }
  sMasterConfig.MasterOutputTrigger = TIM_TRGO_RESET;
  sMasterConfig.MasterSlaveMode = TIM_MASTERSLAVEMODE_DISABLE;
  if (HAL_TIMEx_MasterConfigSynchronization(&htim3, &sMasterConfig) != HAL_OK)
  {
    Error_Handler();
  }

}

static void MX_TIM4_Init(void)
{

  TIM_ClockConfigTypeDef sClockSourceConfig = {0};
  TIM_MasterConfigTypeDef sMasterConfig = {0};
  TIM_IC_InitTypeDef sConfigIC = {0};

  htim4.Instance = TIM4;
  htim4.Init.Prescaler = 89;
  htim4.Init.CounterMode = TIM_COUNTERMODE_UP;
  htim4.Init.Period = 65535;
  htim4.Init.ClockDivision = TIM_CLOCKDIVISION_DIV1;
  htim4.Init.AutoReloadPreload = TIM_AUTORELOAD_PRELOAD_DISABLE;
  if (HAL_TIM_Base_Init(&htim4) != HAL_OK)
  {
    Error_Handler();
  }
  sClockSourceConfig.ClockSource = TIM_CLOCKSOURCE_INTERNAL;
  if (HAL_TIM_ConfigClockSource(&htim4, &sClockSourceConfig) != HAL_OK)
  {
    Error_Handler();
  }
  if (HAL_TIM_IC_Init(&htim4) != HAL_OK)
  {
    Error_Handler();
  }
  sMasterConfig.MasterOutputTrigger = TIM_TRGO_RESET;
  sMasterConfig.MasterSlaveMode = TIM_MASTERSLAVEMODE_DISABLE;
  if (HAL_TIMEx_MasterConfigSynchronization(&htim4, &sMasterConfig) != HAL_OK)
  {
    Error_Handler();
  }
  sConfigIC.ICPolarity = TIM_INPUTCHANNELPOLARITY_RISING;
  sConfigIC.ICSelection = TIM_ICSELECTION_DIRECTTI;
  sConfigIC.ICPrescaler = TIM_ICPSC_DIV1;
  sConfigIC.ICFilter = 4;
  if (HAL_TIM_IC_ConfigChannel(&htim4, &sConfigIC, TIM_CHANNEL_1) != HAL_OK)
  {
    Error_Handler();
  }
  if (HAL_TIM_IC_ConfigChannel(&htim4, &sConfigIC, TIM_CHANNEL_2) != HAL_OK)
  {
    Error_Handler();
  }
  if (HAL_TIM_IC_ConfigChannel(&htim4, &sConfigIC, TIM_CHANNEL_3) != HAL_OK)
  {
    Error_Handler();
  }
  if (HAL_TIM_IC_ConfigChannel(&htim4, &sConfigIC, TIM_CHANNEL_4) != HAL_OK)
  {
    Error_Handler();
  }

}

static void MX_TIM7_Init(void)
{

  TIM_MasterConfigTypeDef sMasterConfig = {0};

  htim7.Instance = TIM7;
  htim7.Init.Prescaler = 168-1;
  htim7.Init.CounterMode = TIM_COUNTERMODE_UP;
  htim7.Init.Period = 65535;
  htim7.Init.AutoReloadPreload = TIM_AUTORELOAD_PRELOAD_DISABLE;
  if (HAL_TIM_Base_Init(&htim7) != HAL_OK)
  {
    Error_Handler();
  }
  sMasterConfig.MasterOutputTrigger = TIM_TRGO_RESET;
  sMasterConfig.MasterSlaveMode = TIM_MASTERSLAVEMODE_DISABLE;
  if (HAL_TIMEx_MasterConfigSynchronization(&htim7, &sMasterConfig) != HAL_OK)
  {
    Error_Handler();
  }

}

static void MX_TIM9_Init(void)
{

  TIM_ClockConfigTypeDef sClockSourceConfig = {0};
  TIM_OC_InitTypeDef sConfigOC = {0};

  htim9.Instance = TIM9;
  htim9.Init.Prescaler = 179;
  htim9.Init.CounterMode = TIM_COUNTERMODE_UP;
  htim9.Init.Period = 10000-1;
  htim9.Init.ClockDivision = TIM_CLOCKDIVISION_DIV1;
  htim9.Init.AutoReloadPreload = TIM_AUTORELOAD_PRELOAD_ENABLE;
  if (HAL_TIM_Base_Init(&htim9) != HAL_OK)
  {
    Error_Handler();
  }
  sClockSourceConfig.ClockSource = TIM_CLOCKSOURCE_INTERNAL;
  if (HAL_TIM_ConfigClockSource(&htim9, &sClockSourceConfig) != HAL_OK)
  {
    Error_Handler();
  }
  if (HAL_TIM_OC_Init(&htim9) != HAL_OK)
  {
    Error_Handler();
  }
  sConfigOC.OCMode = TIM_OCMODE_TIMING;
  sConfigOC.Pulse = 0;
  sConfigOC.OCPolarity = TIM_OCPOLARITY_HIGH;
  sConfigOC.OCFastMode = TIM_OCFAST_DISABLE;
  if (HAL_TIM_OC_ConfigChannel(&htim9, &sConfigOC, TIM_CHANNEL_1) != HAL_OK)
  {
    Error_Handler();
  }

}

static void MX_TIM10_Init(void)
{

  TIM_OC_InitTypeDef sConfigOC = {0};

  htim10.Instance = TIM10;
  htim10.Init.Prescaler = 1499;
  htim10.Init.CounterMode = TIM_COUNTERMODE_UP;
  htim10.Init.Period = 65535;
  htim10.Init.ClockDivision = TIM_CLOCKDIVISION_DIV1;
  htim10.Init.AutoReloadPreload = TIM_AUTORELOAD_PRELOAD_ENABLE;
  if (HAL_TIM_Base_Init(&htim10) != HAL_OK)
  {
    Error_Handler();
  }
  if (HAL_TIM_PWM_Init(&htim10) != HAL_OK)
  {
    Error_Handler();
  }
  sConfigOC.OCMode = TIM_OCMODE_PWM1;
  sConfigOC.Pulse = 0;
  sConfigOC.OCPolarity = TIM_OCPOLARITY_HIGH;
  sConfigOC.OCFastMode = TIM_OCFAST_DISABLE;
  if (HAL_TIM_PWM_ConfigChannel(&htim10, &sConfigOC, TIM_CHANNEL_1) != HAL_OK)
  {
    Error_Handler();
  }
  HAL_TIM_MspPostInit(&htim10);

}

static void MX_TIM11_Init(void)
{

  TIM_OC_InitTypeDef sConfigOC = {0};

  htim11.Instance = TIM11;
  htim11.Init.Prescaler = 1499;
  htim11.Init.CounterMode = TIM_COUNTERMODE_UP;
  htim11.Init.Period = 65535;
  htim11.Init.ClockDivision = TIM_CLOCKDIVISION_DIV1;
  htim11.Init.AutoReloadPreload = TIM_AUTORELOAD_PRELOAD_ENABLE;
  if (HAL_TIM_Base_Init(&htim11) != HAL_OK)
  {
    Error_Handler();
  }
  if (HAL_TIM_PWM_Init(&htim11) != HAL_OK)
  {
    Error_Handler();
  }
  sConfigOC.OCMode = TIM_OCMODE_PWM1;
  sConfigOC.Pulse = 0;
  sConfigOC.OCPolarity = TIM_OCPOLARITY_HIGH;
  sConfigOC.OCFastMode = TIM_OCFAST_DISABLE;
  if (HAL_TIM_PWM_ConfigChannel(&htim11, &sConfigOC, TIM_CHANNEL_1) != HAL_OK)
  {
    Error_Handler();
  }
  HAL_TIM_MspPostInit(&htim11);

}

static void MX_TIM12_Init(void)
{

  TIM_ClockConfigTypeDef sClockSourceConfig = {0};
  TIM_OC_InitTypeDef sConfigOC = {0};

  htim12.Instance = TIM12;
  htim12.Init.Prescaler = 749;
  htim12.Init.CounterMode = TIM_COUNTERMODE_UP;
  htim12.Init.Period = 65535;
  htim12.Init.ClockDivision = TIM_CLOCKDIVISION_DIV1;
  htim12.Init.AutoReloadPreload = TIM_AUTORELOAD_PRELOAD_ENABLE;
  if (HAL_TIM_Base_Init(&htim12) != HAL_OK)
  {
    Error_Handler();
  }
  sClockSourceConfig.ClockSource = TIM_CLOCKSOURCE_INTERNAL;
  if (HAL_TIM_ConfigClockSource(&htim12, &sClockSourceConfig) != HAL_OK)
  {
    Error_Handler();
  }
  if (HAL_TIM_PWM_Init(&htim12) != HAL_OK)
  {
    Error_Handler();
  }
  sConfigOC.OCMode = TIM_OCMODE_PWM1;
  sConfigOC.Pulse = 0;
  sConfigOC.OCPolarity = TIM_OCPOLARITY_HIGH;
  sConfigOC.OCFastMode = TIM_OCFAST_DISABLE;
  if (HAL_TIM_PWM_ConfigChannel(&htim12, &sConfigOC, TIM_CHANNEL_1) != HAL_OK)
  {
    Error_Handler();
  }
  HAL_TIM_MspPostInit(&htim12);

}

static void MX_TIM13_Init(void)
{

  TIM_OC_InitTypeDef sConfigOC = {0};

  htim13.Instance = TIM13;
  htim13.Init.Prescaler = 749;
  htim13.Init.CounterMode = TIM_COUNTERMODE_UP;
  htim13.Init.Period = 65535;
  htim13.Init.ClockDivision = TIM_CLOCKDIVISION_DIV1;
  htim13.Init.AutoReloadPreload = TIM_AUTORELOAD_PRELOAD_ENABLE;
  if (HAL_TIM_Base_Init(&htim13) != HAL_OK)
  {
    Error_Handler();
  }
  if (HAL_TIM_PWM_Init(&htim13) != HAL_OK)
  {
    Error_Handler();
  }
  sConfigOC.OCMode = TIM_OCMODE_PWM1;
  sConfigOC.Pulse = 0;
  sConfigOC.OCPolarity = TIM_OCPOLARITY_HIGH;
  sConfigOC.OCFastMode = TIM_OCFAST_DISABLE;
  if (HAL_TIM_PWM_ConfigChannel(&htim13, &sConfigOC, TIM_CHANNEL_1) != HAL_OK)
  {
    Error_Handler();
  }
  HAL_TIM_MspPostInit(&htim13);

}

static void MX_UART4_Init(void)
{

  huart4.Instance = UART4;
  huart4.Init.BaudRate = 115200;
  huart4.Init.WordLength = UART_WORDLENGTH_8B;
  huart4.Init.StopBits = UART_STOPBITS_1;
  huart4.Init.Parity = UART_PARITY_NONE;
  huart4.Init.Mode = UART_MODE_TX_RX;
  huart4.Init.HwFlowCtl = UART_HWCONTROL_NONE;
  huart4.Init.OverSampling = UART_OVERSAMPLING_16;
  if (HAL_UART_Init(&huart4) != HAL_OK)
  {
    Error_Handler();
  }

}

static void MX_USART3_UART_Init(void)
{

  huart3.Instance = USART3;
  huart3.Init.BaudRate = 921600;
  huart3.Init.WordLength = UART_WORDLENGTH_8B;
  huart3.Init.StopBits = UART_STOPBITS_1;
  huart3.Init.Parity = UART_PARITY_NONE;
  huart3.Init.Mode = UART_MODE_TX_RX;
  huart3.Init.HwFlowCtl = UART_HWCONTROL_NONE;
  huart3.Init.OverSampling = UART_OVERSAMPLING_16;
  if (HAL_UART_Init(&huart3) != HAL_OK)
  {
    Error_Handler();
  }

}

static void MX_USB_OTG_FS_PCD_Init(void)
{

  hpcd_USB_OTG_FS.Instance = USB_OTG_FS;
  hpcd_USB_OTG_FS.Init.dev_endpoints = 6;
  hpcd_USB_OTG_FS.Init.speed = PCD_SPEED_FULL;
  hpcd_USB_OTG_FS.Init.dma_enable = DISABLE;
  hpcd_USB_OTG_FS.Init.phy_itface = PCD_PHY_EMBEDDED;
  hpcd_USB_OTG_FS.Init.Sof_enable = DISABLE;
  hpcd_USB_OTG_FS.Init.low_power_enable = DISABLE;
  hpcd_USB_OTG_FS.Init.lpm_enable = DISABLE;
  hpcd_USB_OTG_FS.Init.vbus_sensing_enable = DISABLE;
  hpcd_USB_OTG_FS.Init.use_dedicated_ep1 = DISABLE;
  if (HAL_PCD_Init(&hpcd_USB_OTG_FS) != HAL_OK)
  {
    Error_Handler();
  }

}

static void MX_DMA_Init(void)
{

  /* DMA controller clock enable */
  __HAL_RCC_DMA1_CLK_ENABLE();

  /* DMA interrupt init */
  /* DMA1_Stream1_IRQn interrupt configuration */
  HAL_NVIC_SetPriority(DMA1_Stream1_IRQn, 5, 0);
  HAL_NVIC_EnableIRQ(DMA1_Stream1_IRQn);
  /* DMA1_Stream3_IRQn interrupt configuration */
  HAL_NVIC_SetPriority(DMA1_Stream3_IRQn, 5, 0);
  HAL_NVIC_EnableIRQ(DMA1_Stream3_IRQn);

}

static void MX_GPIO_Init(void)
{
  GPIO_InitTypeDef GPIO_InitStruct = {0};

  /* GPIO Ports Clock Enable */
  __HAL_RCC_GPIOE_CLK_ENABLE();
  __HAL_RCC_GPIOF_CLK_ENABLE();
  __HAL_RCC_GPIOH_CLK_ENABLE();
  __HAL_RCC_GPIOC_CLK_ENABLE();
  __HAL_RCC_GPIOA_CLK_ENABLE();
  __HAL_RCC_GPIOG_CLK_ENABLE();
  __HAL_RCC_GPIOB_CLK_ENABLE();
  __HAL_RCC_GPIOD_CLK_ENABLE();

  /*Configure GPIO pin Output Level */
  HAL_GPIO_WritePin(GPIOF, LED_EN1_Pin|LED_EN2_Pin|LED_EN3_Pin|EN_DRAWER_Pin
                          |DIR_DRAWER_Pin|EN_Y_Pin|DIR_Y_Pin|PD_CS_Pin
                          |LD_CS_Pin|RESET_Pin, GPIO_PIN_RESET);

  /*Configure GPIO pin Output Level */
  HAL_GPIO_WritePin(HEAT_EN_GPIO_Port, HEAT_EN_Pin, GPIO_PIN_RESET);

  /*Configure GPIO pin Output Level */
  HAL_GPIO_WritePin(GPIOB, EN_X_Pin|DIR_X_Pin|EN_HEATPUMP_Pin|DIR_HEATPUMP_Pin, GPIO_PIN_RESET);

  /*Configure GPIO pin Output Level */
  HAL_GPIO_WritePin(GPIOG, LED_0_Pin|LED_1_Pin, GPIO_PIN_RESET);

  /*Configure GPIO pin : BTN_IN_Pin */
  GPIO_InitStruct.Pin = BTN_IN_Pin;
  GPIO_InitStruct.Mode = GPIO_MODE_INPUT;
  GPIO_InitStruct.Pull = GPIO_NOPULL;
  HAL_GPIO_Init(BTN_IN_GPIO_Port, &GPIO_InitStruct);

  /*Configure GPIO pins : LED_EN1_Pin LED_EN2_Pin LED_EN3_Pin EN_DRAWER_Pin
                           DIR_DRAWER_Pin EN_Y_Pin DIR_Y_Pin PD_CS_Pin
                           LD_CS_Pin RESET_Pin */
  GPIO_InitStruct.Pin = LED_EN1_Pin|LED_EN2_Pin|LED_EN3_Pin|EN_DRAWER_Pin
                          |DIR_DRAWER_Pin|EN_Y_Pin|DIR_Y_Pin|PD_CS_Pin
                          |LD_CS_Pin|RESET_Pin;
  GPIO_InitStruct.Mode = GPIO_MODE_OUTPUT_PP;
  GPIO_InitStruct.Pull = GPIO_NOPULL;
  GPIO_InitStruct.Speed = GPIO_SPEED_FREQ_LOW;
  HAL_GPIO_Init(GPIOF, &GPIO_InitStruct);

  /*Configure GPIO pin : HEAT_EN_Pin */
  GPIO_InitStruct.Pin = HEAT_EN_Pin;
  GPIO_InitStruct.Mode = GPIO_MODE_OUTPUT_PP;
  GPIO_InitStruct.Pull = GPIO_NOPULL;
  GPIO_InitStruct.Speed = GPIO_SPEED_FREQ_LOW;
  HAL_GPIO_Init(HEAT_EN_GPIO_Port, &GPIO_InitStruct);

  /*Configure GPIO pins : GPIO_0_Pin GPIO_1_Pin GPIO_2_Pin GPIO_3_Pin
                           GPIO_4_Pin GPIO_5_Pin GPIO_6_Pin GPIO_7_Pin */
  GPIO_InitStruct.Pin = GPIO_0_Pin|GPIO_1_Pin|GPIO_2_Pin|GPIO_3_Pin
                          |GPIO_4_Pin|GPIO_5_Pin|GPIO_6_Pin|GPIO_7_Pin;
  GPIO_InitStruct.Mode = GPIO_MODE_INPUT;
  GPIO_InitStruct.Pull = GPIO_NOPULL;
  HAL_GPIO_Init(GPIOG, &GPIO_InitStruct);

  /*Configure GPIO pins : EN_X_Pin DIR_X_Pin EN_HEATPUMP_Pin DIR_HEATPUMP_Pin */
  GPIO_InitStruct.Pin = EN_X_Pin|DIR_X_Pin|EN_HEATPUMP_Pin|DIR_HEATPUMP_Pin;
  GPIO_InitStruct.Mode = GPIO_MODE_OUTPUT_PP;
  GPIO_InitStruct.Pull = GPIO_NOPULL;
  GPIO_InitStruct.Speed = GPIO_SPEED_FREQ_LOW;
  HAL_GPIO_Init(GPIOB, &GPIO_InitStruct);

  /*Configure GPIO pins : FAULT_DRAWER_Pin FAULT_HEATPUMP_Pin FAULT_X_Pin LIMIT0_Pin
                           LIMIT1_Pin LIMIT2_Pin LIMIT3_Pin LIMIT4_Pin
                           LIMIT5_Pin LIMIT6_Pin LIMIT7_Pin */
  GPIO_InitStruct.Pin = FAULT_DRAWER_Pin|FAULT_HEATPUMP_Pin|FAULT_X_Pin|LIMIT0_Pin
                          |LIMIT1_Pin|LIMIT2_Pin|LIMIT3_Pin|LIMIT4_Pin
                          |LIMIT5_Pin|LIMIT6_Pin|LIMIT7_Pin;
  GPIO_InitStruct.Mode = GPIO_MODE_IT_FALLING;
  GPIO_InitStruct.Pull = GPIO_NOPULL;
  HAL_GPIO_Init(GPIOD, &GPIO_InitStruct);

  /*Configure GPIO pin : FAULT_Y_Pin */
  GPIO_InitStruct.Pin = FAULT_Y_Pin;
  GPIO_InitStruct.Mode = GPIO_MODE_IT_RISING;
  GPIO_InitStruct.Pull = GPIO_NOPULL;
  HAL_GPIO_Init(FAULT_Y_GPIO_Port, &GPIO_InitStruct);

  /*Configure GPIO pins : LED_0_Pin LED_1_Pin */
  GPIO_InitStruct.Pin = LED_0_Pin|LED_1_Pin;
  GPIO_InitStruct.Mode = GPIO_MODE_OUTPUT_PP;
  GPIO_InitStruct.Pull = GPIO_NOPULL;
  GPIO_InitStruct.Speed = GPIO_SPEED_FREQ_LOW;
  HAL_GPIO_Init(GPIOG, &GPIO_InitStruct);

  /* EXTI interrupt init*/
  HAL_NVIC_SetPriority(EXTI0_IRQn, 5, 0);
  HAL_NVIC_EnableIRQ(EXTI0_IRQn);

  HAL_NVIC_SetPriority(EXTI1_IRQn, 5, 0);
  HAL_NVIC_EnableIRQ(EXTI1_IRQn);

  HAL_NVIC_SetPriority(EXTI2_IRQn, 5, 0);
  HAL_NVIC_EnableIRQ(EXTI2_IRQn);

  HAL_NVIC_SetPriority(EXTI3_IRQn, 5, 0);
  HAL_NVIC_EnableIRQ(EXTI3_IRQn);

  HAL_NVIC_SetPriority(EXTI4_IRQn, 5, 0);
  HAL_NVIC_EnableIRQ(EXTI4_IRQn);

  HAL_NVIC_SetPriority(EXTI9_5_IRQn, 5, 0);
  HAL_NVIC_EnableIRQ(EXTI9_5_IRQn);

  HAL_NVIC_SetPriority(EXTI15_10_IRQn, 5, 0);
  HAL_NVIC_EnableIRQ(EXTI15_10_IRQn);

}

/* USER CODE BEGIN 4 */

void HAL_UART_RxCpltCallback(UART_HandleTypeDef *huart)
{
}

void HAL_UART_TxCpltCallback(UART_HandleTypeDef *huart)
{
  if (huart->Instance == USART3)
  {
    logging_UART_TxCpltCallback(huart);
  }
}

void StartOpticsTask(void *argument)
{
  uint16_t val1 = 0;
  uint16_t val2 = 100;
  uint16_t req_mask = 0x05; /* ADC channels to capture: CH0 and CH2. */

  if(optics_init() != HAL_OK) Error_Handler();

  optics_clearBuffer_byMask(0x0f);

  /* Set initial laser powers and start the free-running SCAN. */
  if(optics_startLaser_byMask(0x01, val1) != HAL_OK) Error_Handler();
  if(optics_startLaser_byMask(0x02, val2) != HAL_OK) Error_Handler();
  /* ADC mask is per raw chip channel: CH0 = 0x01, CH2 = 0x04 -> 0x05 */
  optics_clearBuffer_byMask(req_mask);
  optics_adcStart(req_mask);

  if (optics_get_active_optics_mask() != 0 && (htim9.Instance->CR1 & TIM_CR1_CEN) == 0)
  {
    HAL_TIM_Base_Start_IT(&htim9);
  }

  uint32_t last_dump_ms = HAL_GetTick();

  /* Infinite loop */
  for(;;)
  {
    /* Yield to the scheduler so logging/idle/lower-prio tasks can run.
     * Without this the bare for(;;) busy-loops, starving the UART DMA
     * pump and stretching the effective dump period well past 100 ms. */
    osDelay(1);

    /* Every 100 ms: dump captured samples and roll the buffers. */
    if ((HAL_GetTick() - last_dump_ms) >= 100u) {
      last_dump_ms += 100u;  /* fixed cadence; don't drift with work time */

      uint8_t *buf = NULL;
      uint16_t buf_len = 0;

      optics_adcStop(req_mask);
      if (optics_get_active_optics_mask() == 0)
      {
        HAL_TIM_Base_Stop_IT(&htim9);
      }

      if (optics_getBuffer_byMask(0x01, &buf, &buf_len) == HAL_OK) {
        uint16_t sample_count = buf_len / 2;
        uint16_t n = sample_count < 5u ? sample_count : 5u;
        printf("Optics[0] ch %d samples %u (laser=%u):\r\n", 0, sample_count, val1);
        for (uint16_t i = 0; i < n; i++) {
          uint16_t sample = ((uint16_t)buf[i * 2] << 8) | buf[i * 2 + 1];
          printf(" (0x%04X) ", sample);
        }
      }
      printf("\r\n");

      if (optics_getBuffer_byMask(0x04, &buf, &buf_len) == HAL_OK) {
        uint16_t sample_count = buf_len / 2;
        uint16_t n = sample_count < 5u ? sample_count : 5u;
        printf("Optics[0] ch %d samples %u (laser=%u):\r\n", 2, sample_count, val2);
        for (uint16_t i = 0; i < n; i++) {
          uint16_t sample = ((uint16_t)buf[i * 2] << 8) | buf[i * 2 + 1];
          printf(" (0x%04X) ", sample);
        }
      }
      printf("\r\n\r\n");

      /* Reset buffers for the next window: clear chip channels 0 and 2. */
      optics_clearBuffer_byMask(0x05);

      /* Step the laser powers. */
      val1 += 10; if (val1 > 100) val1 = 0;
      val2 -= 10; if (val2 < 1)   val2 = 100;
      (void)optics_startLaser_byMask(0x01, val1);
      (void)optics_startLaser_byMask(0x02, val2);

      optics_adcStart(req_mask);

      if (optics_get_active_optics_mask() != 0 && (htim9.Instance->CR1 & TIM_CR1_CEN) == 0)
      {
        HAL_TIM_Base_Start_IT(&htim9);
      }

    }

  }

}

/* USER CODE END 4 */

void StartDefaultTask(void *argument)
{
  for(;;)
  {
    osDelay(1);
  }
}

void HAL_TIM_PeriodElapsedCallback(TIM_HandleTypeDef *htim)
{
  if (htim->Instance == TIM14)
  {
    HAL_IncTick();
  }
  /* USER CODE BEGIN Callback 1 */

  if (htim->Instance == TIM9) {
	  /* Defer the SPI work to the main loop. */
    (void)optics_adcRead();
  }
  /* USER CODE END Callback 1 */
}

void Error_Handler(void)
{
  __disable_irq();
  while (1)
  {
  }
}
